AUTOSAR XML (schema 00044)
package /E40_Platform_System_SystemPackage/Components
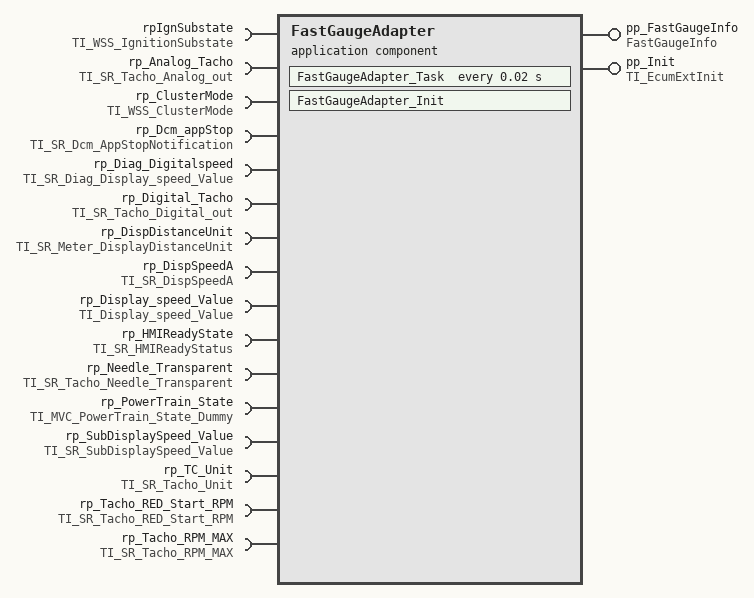
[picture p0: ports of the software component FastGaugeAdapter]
  application sw component type FastGaugeAdapter
    provide port pp_FastGaugeInfo: nonqueued-sender-com-spec{data-element=FastGaugeInfoData, init-value=constant-reference=SFastGaugeInfo_InitValue}, provided-interface=FastGaugeInfo
    provide port pp_Init: server-com-spec{operation=Init, queue-length=1}, provided-interface=TI_EcumExtInit
    16 x require port:
      rpIgnSubstate: nonqueued-receiver-com-spec{data-element=IgnitionSubstate, filter=data-filter-type=ALWAYS, init-value=constant-reference=FastGaugeAdapterIgnitionSubstateValue0}, required-interface=TI_WSS_IgnitionSubstate
      rp_Analog_Tacho: nonqueued-receiver-com-spec{data-element=Analog_Tacho, filter=data-filter-type=ALWAYS, init-value=constant-reference=FastGaugeAdapterAnalog_TachoValue0}, required-interface=TI_SR_Tacho_Analog_out
      rp_ClusterMode: nonqueued-receiver-com-spec{data-element=WSSCurrentClusterMode, filter=data-filter-type=ALWAYS, init-value=constant-reference=FastGaugeAdapterWSSCurrentClusterModeValue0}, required-interface=TI_WSS_ClusterMode
      rp_Dcm_appStop: nonqueued-receiver-com-spec{data-element=AppId, filter=data-filter-type=ALWAYS, init-value=constant-reference=FastGaugeAdapterAppIdValue0}, required-interface=TI_SR_Dcm_AppStopNotification
      rp_Diag_Digitalspeed: nonqueued-receiver-com-spec{data-element=Diag_Digital_Speed_Value, filter=data-filter-type=ALWAYS, init-value=constant-reference=FastGaugeAdapterDiag_Digital_Speed_ValueValue0}, required-interface=TI_SR_Diag_Display_speed_Value
      rp_Digital_Tacho: nonqueued-receiver-com-spec{data-element=Digital_Tacho, filter=data-filter-type=ALWAYS, init-value=constant-reference=FastGaugeAdapterDigital_TachoValue0}, required-interface=TI_SR_Tacho_Digital_out
      rp_DispDistanceUnit: nonqueued-receiver-com-spec{data-element=DisplayUnit, filter=data-filter-type=ALWAYS, init-value=constant-reference=FastGaugeAdapterDisplayUnitValue0}, required-interface=TI_SR_Meter_DisplayDistanceUnit
      rp_DispSpeedA: nonqueued-receiver-com-spec{data-element=DispSpeedVal, filter=data-filter-type=ALWAYS, init-value=constant-reference=FastGaugeAdapterDispSpeedValValue0}, required-interface=TI_SR_DispSpeedA
      rp_Display_speed_Value: nonqueued-receiver-com-spec{data-element=Digital_Speed_Value, filter=data-filter-type=ALWAYS, init-value=constant-reference=FastGaugeAdapterDigital_Speed_ValueValue0}, required-interface=TI_Display_speed_Value
      rp_HMIReadyState: nonqueued-receiver-com-spec{data-element=HMI_ReadyStatus, filter=data-filter-type=ALWAYS, init-value=constant-reference=FastGaugeAdapterHMI_ReadyStatusValue0}, required-interface=TI_SR_HMIReadyStatus
      rp_Needle_Transparent: nonqueued-receiver-com-spec{data-element=Needle_TR, filter=data-filter-type=ALWAYS, init-value=constant-reference=FastGaugeAdapterNeedle_TRValue0}, required-interface=TI_SR_Tacho_Needle_Transparent
      rp_PowerTrain_State: nonqueued-receiver-com-spec{data-element=PowerTrain_Flag, filter=data-filter-type=ALWAYS, init-value=constant-reference=FastGaugeAdapterPowerTrain_FlagValue0}, required-interface=TI_MVC_PowerTrain_State_Dummy
      rp_SubDisplaySpeed_Value: nonqueued-receiver-com-spec{data-element=SubDispSpeedVal, filter=data-filter-type=ALWAYS, init-value=constant-reference=FastGaugeAdapterSubDispSpeedValValue0}, required-interface=TI_SR_SubDisplaySpeed_Value
      rp_TC_Unit: nonqueued-receiver-com-spec{data-element=Digital_TachoUnit, filter=data-filter-type=ALWAYS, init-value=constant-reference=FastGaugeAdapterDigital_TachoUnitValue0}, required-interface=TI_SR_Tacho_Unit
      rp_Tacho_RED_Start_RPM: nonqueued-receiver-com-spec{data-element=RED_Start_RPM, filter=data-filter-type=ALWAYS, init-value=constant-reference=FastGaugeAdapterRED_Start_RPMValue0}, required-interface=TI_SR_Tacho_RED_Start_RPM
      rp_Tacho_RPM_MAX: nonqueued-receiver-com-spec{data-element=REVP_RPM_MAX, filter=data-filter-type=ALWAYS, init-value=constant-reference=FastGaugeAdapterREVP_RPM_MAXValue0}, required-interface=TI_SR_Tacho_RPM_MAX
    behavior IB_FastGaugeAdapter
      operation invoked event OIE_pp_Init_FastGaugeAdapter_InitTrigByInit: start-on-event=FastGaugeAdapter_Init, operation=pp_Init.Init
      timing event TEFastGaugeAdapter_Task: start-on-event=FastGaugeAdapter_Task, period=0.02
      port-api-options:
        enable-take-address=false, error-handling=NO-TRANSFORMER-ERROR-HANDLING, indirect-api=false, port=pp_FastGaugeInfo
        enable-take-address=false, error-handling=NO-TRANSFORMER-ERROR-HANDLING, indirect-api=false, port=pp_Init
        enable-take-address=false, error-handling=NO-TRANSFORMER-ERROR-HANDLING, indirect-api=false, port=rpIgnSubstate
        enable-take-address=false, error-handling=NO-TRANSFORMER-ERROR-HANDLING, indirect-api=false, port=rp_Analog_Tacho
        enable-take-address=false, error-handling=NO-TRANSFORMER-ERROR-HANDLING, indirect-api=false, port=rp_ClusterMode
        enable-take-address=false, error-handling=NO-TRANSFORMER-ERROR-HANDLING, indirect-api=false, port=rp_Dcm_appStop
        enable-take-address=false, error-handling=NO-TRANSFORMER-ERROR-HANDLING, indirect-api=false, port=rp_Diag_Digitalspeed
        enable-take-address=false, error-handling=NO-TRANSFORMER-ERROR-HANDLING, indirect-api=false, port=rp_Digital_Tacho
        enable-take-address=false, error-handling=NO-TRANSFORMER-ERROR-HANDLING, indirect-api=false, port=rp_DispDistanceUnit
        enable-take-address=false, error-handling=NO-TRANSFORMER-ERROR-HANDLING, indirect-api=false, port=rp_DispSpeedA
        enable-take-address=false, error-handling=NO-TRANSFORMER-ERROR-HANDLING, indirect-api=false, port=rp_Display_speed_Value
        enable-take-address=false, error-handling=NO-TRANSFORMER-ERROR-HANDLING, indirect-api=false, port=rp_HMIReadyState
        enable-take-address=false, error-handling=NO-TRANSFORMER-ERROR-HANDLING, indirect-api=false, port=rp_Needle_Transparent
        enable-take-address=false, error-handling=NO-TRANSFORMER-ERROR-HANDLING, indirect-api=false, port=rp_PowerTrain_State
        enable-take-address=false, error-handling=NO-TRANSFORMER-ERROR-HANDLING, indirect-api=false, port=rp_SubDisplaySpeed_Value
        enable-take-address=false, error-handling=NO-TRANSFORMER-ERROR-HANDLING, indirect-api=false, port=rp_TC_Unit
        enable-take-address=false, error-handling=NO-TRANSFORMER-ERROR-HANDLING, indirect-api=false, port=rp_Tacho_RED_Start_RPM
        enable-take-address=false, error-handling=NO-TRANSFORMER-ERROR-HANDLING, indirect-api=false, port=rp_Tacho_RPM_MAX
      runnable FastGaugeAdapter_Init: can-be-invoked-concurrently=true
      runnable FastGaugeAdapter_Task: can-be-invoked-concurrently=true
        data-receive-point-by-arguments:
          16 x access:
            DRA_rpIgnSubstate_IgnitionSubstate: accessed-variable=rpIgnSubstate.IgnitionSubstate
            DRA_rp_Analog_Tacho_Analog_Tacho: accessed-variable=rp_Analog_Tacho.Analog_Tacho
            DRA_rp_ClusterMode_WSSCurrentClusterMode: accessed-variable=rp_ClusterMode.WSSCurrentClusterMode
            DRA_rp_Dcm_appStop_AppId: accessed-variable=rp_Dcm_appStop.AppId
            DRA_rp_Diag_Digitalspeed_Diag_Digital_Speed_Value: accessed-variable=rp_Diag_Digitalspeed.Diag_Digital_Speed_Value
            DRA_rp_Digital_Tacho_Digital_Tacho: accessed-variable=rp_Digital_Tacho.Digital_Tacho
            DRA_rp_DispDistanceUnit_DisplayUnit: accessed-variable=rp_DispDistanceUnit.DisplayUnit
            DRA_rp_DispSpeedA_DispSpeedVal: accessed-variable=rp_DispSpeedA.DispSpeedVal
            DRA_rp_Display_speed_Value_Digital_Speed_Value: accessed-variable=rp_Display_speed_Value.Digital_Speed_Value
            DRA_rp_HMIReadyState_HMI_ReadyStatus: accessed-variable=rp_HMIReadyState.HMI_ReadyStatus
            DRA_rp_Needle_Transparent_Needle_TR: accessed-variable=rp_Needle_Transparent.Needle_TR
            DRA_rp_PowerTrain_State_PowerTrain_Flag: accessed-variable=rp_PowerTrain_State.PowerTrain_Flag
            DRA_rp_SubDisplaySpeed_Value_SubDispSpeedVal: accessed-variable=rp_SubDisplaySpeed_Value.SubDispSpeedVal
            DRA_rp_TC_Unit_Digital_TachoUnit: accessed-variable=rp_TC_Unit.Digital_TachoUnit
            DRA_rp_Tacho_RED_Start_RPM_RED_Start_RPM: accessed-variable=rp_Tacho_RED_Start_RPM.RED_Start_RPM
            DRA_rp_Tacho_RPM_MAX_REVP_RPM_MAX: accessed-variable=rp_Tacho_RPM_MAX.REVP_RPM_MAX
        data-send-points:
          access DWA_pp_FastGaugeInfo_FastGaugeInfoData: accessed-variable=pp_FastGaugeInfo.FastGaugeInfoData
  swc implementation IMPL_FastGaugeAdapter: behavior=IB_FastGaugeAdapter
    code-descriptors:
      code Default: artifact-descriptors=autosar-engineering-object=category=SWSRC
